# STM32G0B0xx register map
File version: 1.0
Registers are 32-bit, read-write, reset 0x0 unless marked. A register's access mark holds for its fields unless they carry their own. Offsets are from the block's base; [hi:lo] are bit positions; lines under a group give offsets from that group; {n}, {i} and the like mark numbered series.

## ADC1 — Analog to Digital Converter
Base 0x40012400
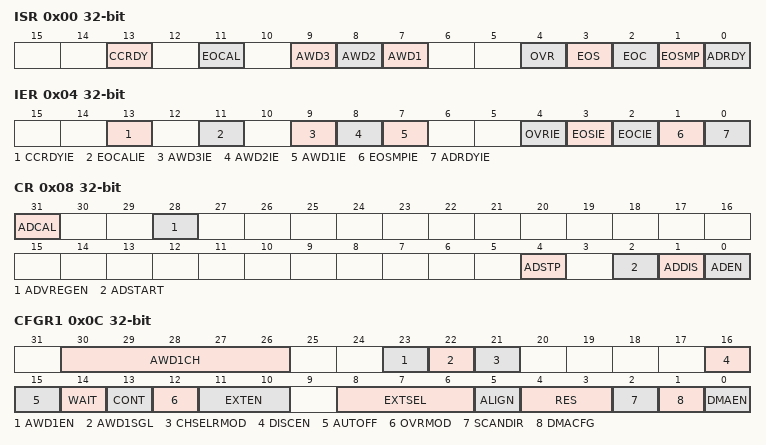
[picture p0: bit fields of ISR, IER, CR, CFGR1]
0x00 ISR — ADC interrupt and status register
  [13] CCRDY — ADC channel configuration ready flag
  [11] EOCAL — ADC end of calibration flag
  [9] AWD3 — ADC analog watchdog 3 flag
  [8] AWD2 — ADC analog watchdog 2 flag
  [7] AWD1 — ADC analog watchdog 1 flag
  [4] OVR — ADC group regular overrun flag
  [3] EOS — ADC group regular end of sequence conversions flag
  [2] EOC — ADC group regular end of unitary conversion flag
  [1] EOSMP — ADC group regular end of sampling flag
  [0] ADRDY — ADC ready flag
0x04 IER — ADC interrupt enable register
  [13] CCRDYIE — ADC channel configuration ready interrupt
  [11] EOCALIE — ADC end of calibration interrupt
  [9] AWD3IE — ADC analog watchdog 3 interrupt
  [8] AWD2IE — ADC analog watchdog 2 interrupt
  [7] AWD1IE — ADC analog watchdog 1 interrupt
  [4] OVRIE — ADC group regular overrun interrupt
  [3] EOSIE — ADC group regular end of sequence conversions interrupt
  [2] EOCIE — ADC group regular end of unitary conversion interrupt
  [1] EOSMPIE — ADC group regular end of sampling interrupt
  [0] ADRDYIE — ADC ready interrupt
0x08 CR — ADC control register
  [31] ADCAL — ADC calibration
  [28] ADVREGEN — ADC voltage regulator enable
  [4] ADSTP — ADC group regular conversion stop
  [2] ADSTART — ADC group regular conversion start
  [1] ADDIS — ADC disable
  [0] ADEN — ADC enable
0x0C CFGR1 — ADC configuration register 1
  [30:26] AWD1CH — ADC analog watchdog 1 monitored channel selection
  [23] AWD1EN — ADC analog watchdog 1 enable on scope ADC group regular
  [22] AWD1SGL — ADC analog watchdog 1 monitoring a single channel or all channels
  [21] CHSELRMOD — ADC group regular sequencer mode
    0=FIXED; 1=CONFIGURABLE
  [16] DISCEN — ADC group regular sequencer discontinuous mode
    0=DISABLE; 1=DISCONT_1RANK
  [15] AUTOFF — ADC low power auto power off
  [14] WAIT — ADC low power auto wait
  [13] CONT — ADC group regular continuous conversion mode
    0=SINGLE; 1=CONTINUOUS
  [12] OVRMOD — ADC group regular overrun configuration
    0=PRESERVED; 1=OVERWRITTEN
  [11:10] EXTEN — ADC group regular external trigger polarity
    1=RISING; 2=FALLING; 3=RISINGFALLING
  [8:6] EXTSEL — ADC group regular external trigger source
  [5] ALIGN — ADC data alignment
    0=RIGHT; 1=LEFT
  [4:3] RES — ADC data resolution
    0=RESOLUTION_12B (ADC resolution 12 bits); 1=RESOLUTION_10B (ADC resolution 10 bits); 2=RESOLUTION_8B (ADC resolution 8 bits); 3=RESOLUTION_6B (ADC resolution 6 bits)
  [2] SCANDIR — ADC group regular sequencer scan direction
    0=FORWARD; 1=BACKWARD
  [1] DMACFG — ADC DMA transfer configuration
  [0] DMAEN — ADC DMA transfer enable
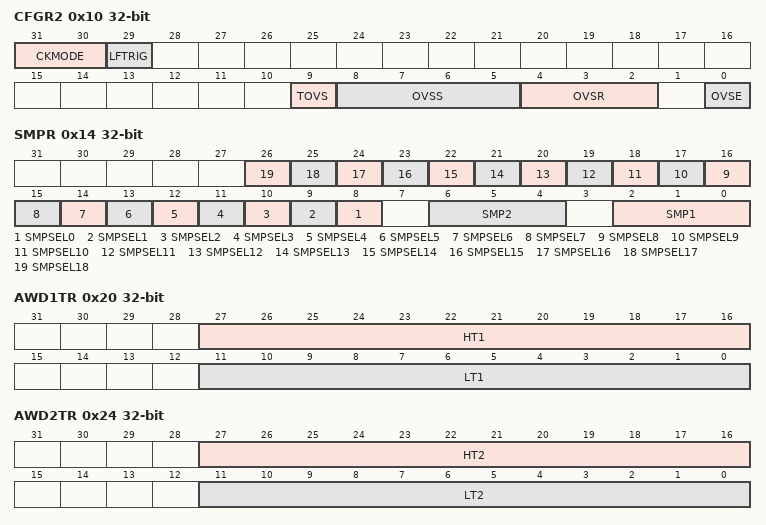
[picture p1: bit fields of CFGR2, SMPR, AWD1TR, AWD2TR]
0x10 CFGR2 — ADC configuration register 2
  [31:30] CKMODE — ADC clock source and prescaler (prescaler only for clock source synchronous)
    2=SYNC_PCLK_DIV4; 1=SYNC_PCLK_DIV2; 3=SYNC_PCLK_DIV1; 0=ASYNC
  [29] LFTRIG — ADC low frequency trigger mode
    0=HIGH; 1=LOW
  [9] TOVS — ADC oversampling discontinuous mode (triggered mode) for ADC group regular
    0=CONT; 1=DISCONT
  [8:5] OVSS — ADC oversampling shift
    0=NONE; {v}=RIGHT_{v} (v=1..8)
  [4:2] OVSR — ADC oversampling ratio
    0=RATIO_2; 1=RATIO_4; 2=RATIO_8; 3=RATIO_16; 4=RATIO_32; 5=RATIO_64; 6=RATIO_128; 7=RATIO_256
  [0] OVSE — ADC oversampler enable on scope ADC group regular
    0=DISABLE (ADC oversampling disabled.); 1=GRP_REGULAR_CONTINUED
0x14 SMPR — ADC sampling time register
  [n+8] SMPSEL{n} (n=0..18) — ADC channel {n} sampling time selection
  [6:4] SMP2 — ADC group of channels sampling time 2
  [2:0] SMP1 — ADC group of channels sampling time 1
0x20 AWD1TR — ADC analog watchdog 1 threshold register
  [27:16] HT1 — ADC Analog watchdog 1 threshold high
  [11:0] LT1 — ADC analog watchdog 1 threshold low
0x24 AWD2TR — ADC analog watchdog 2 threshold register
  [27:16] HT2 — ADC analog watchdog 2 threshold high
  [11:0] LT2 — ADC analog watchdog 2 threshold low
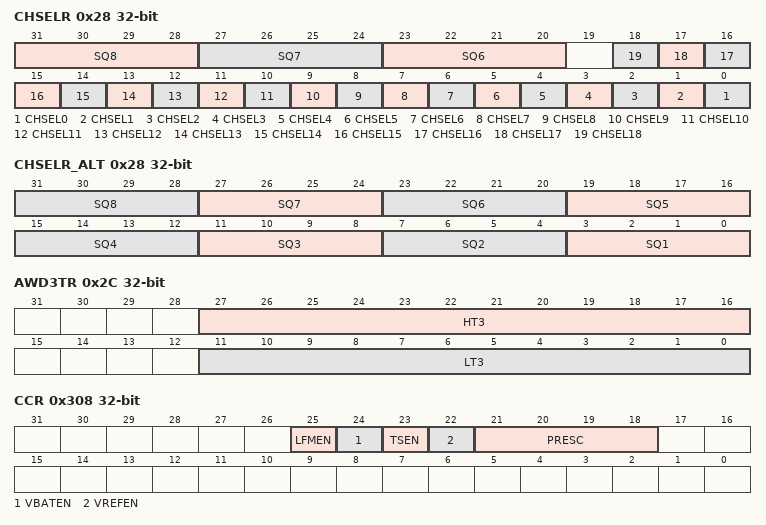
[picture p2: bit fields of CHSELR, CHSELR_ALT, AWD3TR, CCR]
0x28 CHSELR — ADC group regular sequencer register
  [31:28] SQ8 — ADC group regular sequencer rank 8, available when ADC_CFGR1_CHSELRMOD is set
  [27:24] SQ7 — ADC group regular sequencer rank 7, available when ADC_CFGR1_CHSELRMOD is set
  [23:20] SQ6 — ADC group regular sequencer rank 6, available when ADC_CFGR1_CHSELRMOD is set
  [n] CHSEL{n} (n=0..18) — ADC group regular sequencer channel {n}, available when ADC_CFGR1_CHSELRMOD is reset
0x28 CHSELR_ALT (alternate view of CHSELR) — ADC group regular sequencer register
  [4n-1:4n-4] SQ{n} (n=1..8) — ADC group regular sequencer rank {n}, available when ADC_CFGR1_CHSELRMOD is set
0x2C AWD3TR — ADC analog watchdog 3 threshold register
  [27:16] HT3 — ADC analog watchdog 3 threshold high
  [11:0] LT3 — ADC analog watchdog 3 threshold low
0x40 DR — ADC group regular data register
  [15:0] DATA — ADC group regular conversion data
0xA0 AWD2CR — ADC analog watchdog 2 configuration register
  [18:0] AWD2CH — ADC analog watchdog 2 monitored channel selection
0xA4 AWD3CR — ADC analog watchdog 3 configuration register
  [18:0] AWD3CH — ADC analog watchdog 3 monitored channel selection
0xB4 CALFACT — ADC Calibration factor register
  [6:0] CALFACT — ADC calibration factor in single-ended mode
0x308 CCR — ADC common configuration register
  [25] LFMEN — Legacy feature, useless on STM32G0 (ADC common clock low frequency mode is automatically managed by ADC peripheral on STM32G0)
    0=HIGH; 1=LOW
  [24] VBATEN — ADC internal path to battery voltage enable
  [23] TSEN — ADC internal path to temperature sensor enable
  [22] VREFEN — ADC internal path to VrefInt enable
  [21:18] PRESC — ADC common clock prescaler, only for clock source asynchronous
    0=DIV1; 1=DIV2; 2=DIV4; 3=DIV6; 4=DIV8; 5=DIV10; 6=DIV12; 7=DIV16; 8=DIV32; 9=DIV64; 10=DIV128; 11=DIV256
